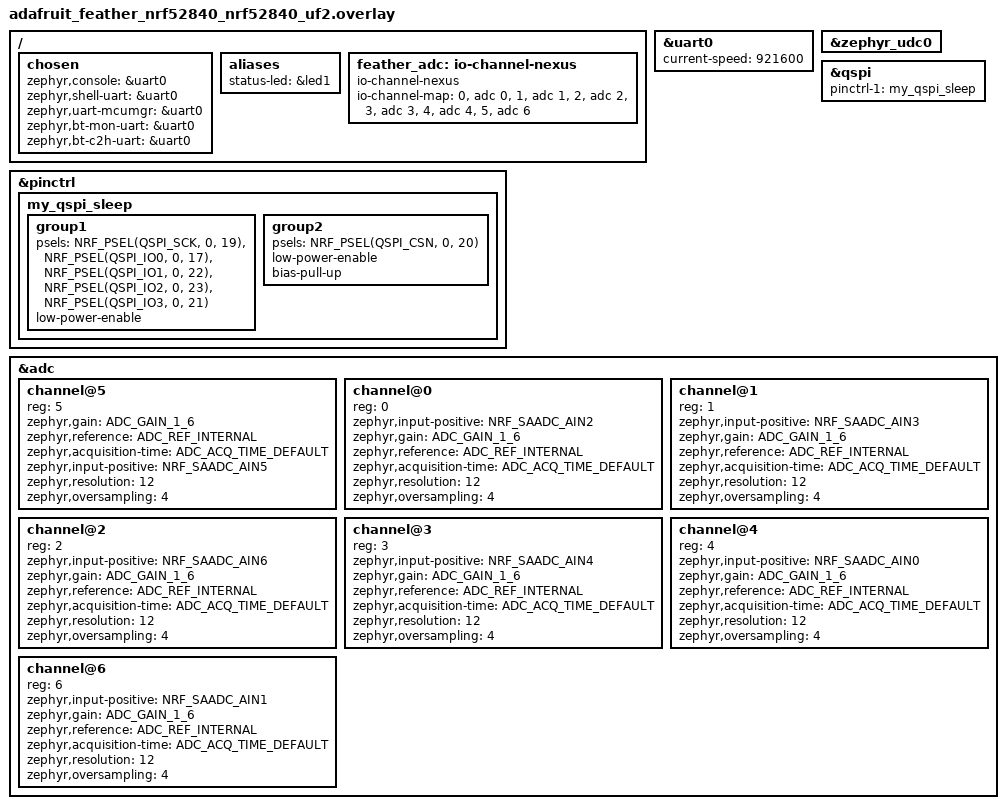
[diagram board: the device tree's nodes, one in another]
/ {
    chosen {
        zephyr,console = &uart0;
        zephyr,shell-uart = &uart0;
        zephyr,uart-mcumgr = &uart0;
        zephyr,bt-mon-uart = &uart0;
        zephyr,bt-c2h-uart = &uart0;
    };

    aliases {
        status-led = &led1;
    };
};

&uart0 {
    current-speed = <921600>;
};

&zephyr_udc0 {
    /delete-node/ board_cdc_acm_uart;
};

&pinctrl {
    my_qspi_sleep: my_qspi_sleep {
        group1 {
            psels = <NRF_PSEL(QSPI_SCK, 0, 19)>,
                <NRF_PSEL(QSPI_IO0, 0, 17)>,
                <NRF_PSEL(QSPI_IO1, 0, 22)>,
                <NRF_PSEL(QSPI_IO2, 0, 23)>,
                <NRF_PSEL(QSPI_IO3, 0, 21)>;
            low-power-enable;
        };
        group2 {
            psels = <NRF_PSEL(QSPI_CSN, 0, 20)>;
            low-power-enable;
            bias-pull-up;
        };
    };
};

&qspi {
    pinctrl-1 = <&my_qspi_sleep>;
};

// The board's own devicetree already defines a /vbatt voltage-divider node
// (io-channels = <&adc 5>), but not the ADC channel config it needs.

#include <zephyr/dt-bindings/adc/adc.h>
#include <zephyr/dt-bindings/adc/nrf-saadc.h>

&adc {
    #address-cells = <1>;
    #size-cells = <0>;

    channel@5 {
        reg = <5>;
        zephyr,gain = "ADC_GAIN_1_6";
        zephyr,reference = "ADC_REF_INTERNAL";
        zephyr,acquisition-time = <ADC_ACQ_TIME_DEFAULT>;
        zephyr,input-positive = <NRF_SAADC_AIN5>;
        zephyr,resolution = <12>;
        zephyr,oversampling = <4>;
    };

    channel@0 {
        reg = <0>; /* A0, P0.04 (AIN2) */
        zephyr,input-positive = <NRF_SAADC_AIN2>;
        zephyr,gain = "ADC_GAIN_1_6";
        zephyr,reference = "ADC_REF_INTERNAL";
        zephyr,acquisition-time = <ADC_ACQ_TIME_DEFAULT>;
        zephyr,resolution = <12>;
        zephyr,oversampling = <4>;
    };

    channel@1 {
        reg = <1>; /* A1, P0.05 (AIN3) */
        zephyr,input-positive = <NRF_SAADC_AIN3>;
        zephyr,gain = "ADC_GAIN_1_6";
        zephyr,reference = "ADC_REF_INTERNAL";
        zephyr,acquisition-time = <ADC_ACQ_TIME_DEFAULT>;
        zephyr,resolution = <12>;
        zephyr,oversampling = <4>;
    };

    channel@2 {
        reg = <2>; /* A2, P0.30 (AIN6) */
        zephyr,input-positive = <NRF_SAADC_AIN6>;
        zephyr,gain = "ADC_GAIN_1_6";
        zephyr,reference = "ADC_REF_INTERNAL";
        zephyr,acquisition-time = <ADC_ACQ_TIME_DEFAULT>;
        zephyr,resolution = <12>;
        zephyr,oversampling = <4>;
    };

    channel@3 {
        reg = <3>; /* A3, P0.28 (AIN4) */
        zephyr,input-positive = <NRF_SAADC_AIN4>;
        zephyr,gain = "ADC_GAIN_1_6";
        zephyr,reference = "ADC_REF_INTERNAL";
        zephyr,acquisition-time = <ADC_ACQ_TIME_DEFAULT>;
        zephyr,resolution = <12>;
        zephyr,oversampling = <4>;
    };

    channel@4 {
        reg = <4>; /* A4, P0.02 (AIN0) */
        zephyr,input-positive = <NRF_SAADC_AIN0>;
        zephyr,gain = "ADC_GAIN_1_6";
        zephyr,reference = "ADC_REF_INTERNAL";
        zephyr,acquisition-time = <ADC_ACQ_TIME_DEFAULT>;
        zephyr,resolution = <12>;
        zephyr,oversampling = <4>;
    };

    channel@6 {
        reg = <6>; /* A5, P0.03 (AIN1) */
        zephyr,input-positive = <NRF_SAADC_AIN1>;
        zephyr,gain = "ADC_GAIN_1_6";
        zephyr,reference = "ADC_REF_INTERNAL";
        zephyr,acquisition-time = <ADC_ACQ_TIME_DEFAULT>;
        zephyr,resolution = <12>;
        zephyr,oversampling = <4>;
    };
};

/ {
    feather_adc: io-channel-nexus {
        compatible = "io-channel-nexus";
        #io-channel-cells = <1>;
        io-channel-map = <0 &adc 0>,  /* A0 */
                          <1 &adc 1>,  /* A1 */
                          <2 &adc 2>,  /* A2 */
                          <3 &adc 3>,  /* A3 */
                          <4 &adc 4>,  /* A4 */
                          <5 &adc 6>;  /* A5, sic */
    };
};
